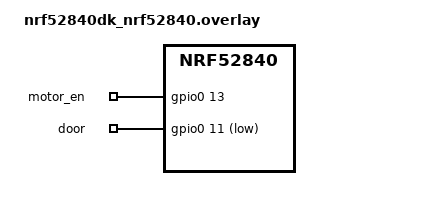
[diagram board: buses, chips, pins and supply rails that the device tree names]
/ {
    lock_motor: lock_motor {
        compatible = "gpio-leds";
        motor_en: motor_en { gpios = <&gpio0 13 GPIO_ACTIVE_HIGH>; };
    };
    door_sensor: door_sensor {
        compatible = "gpio-keys";
        door: door { gpios = <&gpio0 11 (GPIO_PULL_UP | GPIO_ACTIVE_LOW)>; };
    };
};
